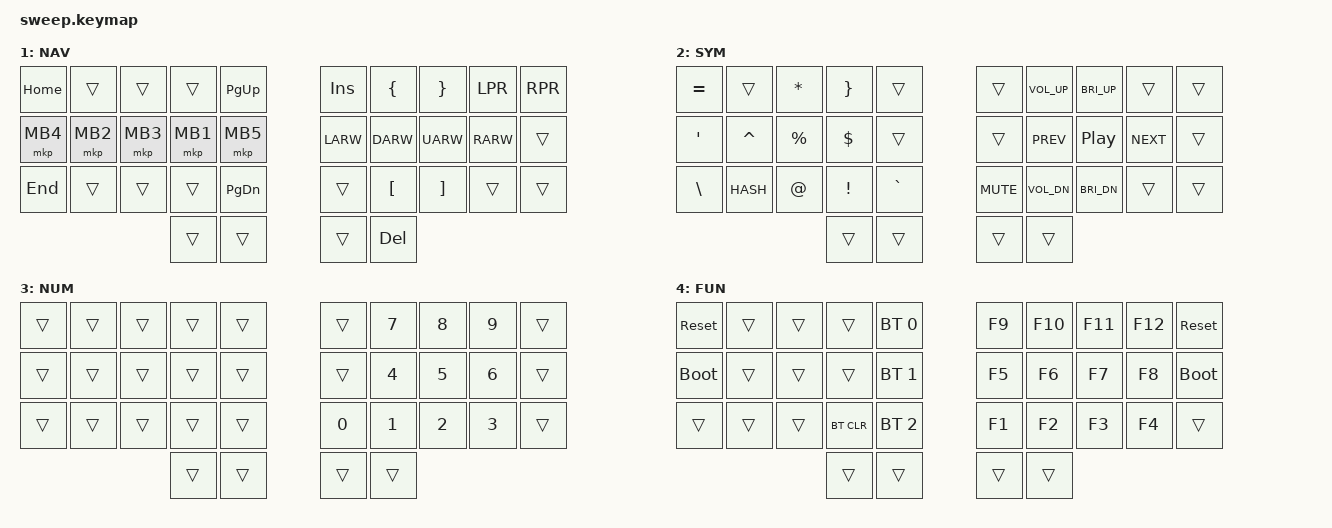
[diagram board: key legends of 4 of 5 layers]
// Copyright (c) 2022 The ZMK Contributors
// SPDX-License-Identifier: MIT

#include <behaviors.dtsi>
#include <dt-bindings/zmk/keys.h>
#include <dt-bindings/zmk/bt.h>

// Layers
#define DEFAULT 0
#define NAV 1
#define SYM 2
#define NUM 3
#define FUN 4

// Home row mods macro
#define HRML(k1,k2,k3,k4) &ht LSHFT k1  &ht LCTRL k2  &ht LALT k3  &ht LGUI k4
#define HRMR(k1,k2,k3,k4) &ht RGUI k1  &ht RALT k2  &ht RCTRL k3  &ht RSHFT k4

/ {
    behaviors {
        ht: hold_tap {
            compatible = "zmk,behavior-hold-tap";
            #binding-cells = <2>;
            flavor = "tap-preferred";
            tapping-term-ms = <220>;
            quick-tap-ms = <150>;
            require-prior-idle-ms = <100>;
            bindings = <&kp>, <&kp>;
        };
    };

    combos {
        compatible = "zmk,combos";
        combo_esc {
            timeout-ms = <50>;
            key-positions = <10 19>;
            bindings = <&kp ESC>;
        };
        combo_minus {
            timeout-ms = <50>;
            key-positions = <14 15>;
            bindings = <&kp MINUS>;
        };
        combo_underscore {
            timeout-ms = <50>;
            key-positions = <24 25>;
            bindings = <&kp UNDER>;
        };
        combo_capsword {
            timeout-ms = <50>;
            key-positions = <20 29>;
            bindings = <&caps_word>;
        };
    };

    keymap {
        compatible = "zmk,keymap";
        DEFAULT {
            bindings = <
        //╭──────────┬──────────┬──────────┬──────────┬──────────╮   ╭──────────┬──────────┬──────────┬──────────┬──────────╮
        //│  Q       │  W       │  F       │  P       │  B       │   │  J       │  L       │  U       │  Y       │  ; :     │
            &kp Q      &kp W      &kp F      &kp P      &kp B          &kp J      &kp L      &kp U      &kp Y      &kp SEMI
        //├──────────┼──────────┼──────────┼──────────┼──────────┤   ├──────────┼──────────┼──────────┼──────────┼──────────┤
        //│  A       │  R       │  S       │  T       │  G       │   │  M       │  N       │  E       │  I       │  O      │
            HRML(A,        R,         S,         T)     &kp G          &kp H      HRMR(N,        E,         I,        O)
        //├──────────┼──────────┼──────────┼──────────┼──────────┤   ├──────────┼──────────┼──────────┼──────────┼──────────┤
        //│  Z       │  X       │  C       │  D       │  V       │   │  K       │  H       │ , <      │ . >      │ / ?      │
            &kp Z      &kp X      &kp C      &kp D      &kp V          &kp N      &kp M      &kp COMMA  &kp DOT    &kp FSLH
        //╰──────────┴──────────┴──────────┼──────────┼──────────┤   ├──────────┼──────────┼──────────┴──────────┴──────────╯
                                        &lt NUM TAB   &lt NAV ENTER  &lt SYM SPACE  &lt FUN BSPC
        //                                 ╰──────────┴──────────╯   ╰──────────┴──────────╯
            >;
        };

        NAV {
            bindings = <
        // vim navigation and mouse actions
        //╭──────────┬──────────┬──────────┬──────────┬──────────╮   ╭──────────┬──────────┬──────────┬──────────┬──────────╮
        //│ Home     │          │          │          │ Page Up  │   │  Insert  │   {      │    }     │   (      │  )       │
            &kp HOME   &trans     &trans     &trans     &kp PG_UP       &kp INS   &kp LBRC   &kp RBRC   &kp LPR    &kp RPR
        //├──────────┼──────────┼──────────┼──────────┼──────────┤   ├──────────┼──────────┼──────────┼──────────┼──────────┤
        //│ MBCK     │  RCLK    │  MCLK    │  LCLK    │  MFWD    │   │ LEFT     │ DOWN     │ UP       │ RIGHT    │          │
            &mkp MB4   &mkp MB2   &mkp MB3   &mkp MB1   &mkp MB5       &kp LARW   &kp DARW   &kp UARW   &kp RARW   &trans
        //├──────────┼──────────┼──────────┼──────────┼──────────┤   ├──────────┼──────────┼──────────┼──────────┼──────────┤
        //│ End      │          |          │          │ Page Down│   │          │    [     │    ]     │          │          │
            &kp END     &trans     &trans     &trans    &kp PG_DN       &trans     &kp LBKT   &kp RBKT   &trans     &trans
        //╰──────────┴──────────┴──────────┼──────────┼──────────┤   ├──────────┼──────────┼──────────┴──────────┴──────────╯
                                             &trans     &trans         &trans     &kp DEL
        //                                 ╰──────────┴──────────╯   ╰──────────┴──────────╯
            >;
        };


        SYM {
            bindings = <
        // symbols and media controls
        //╭──────────┬──────────┬──────────┬──────────┬──────────╮   ╭──────────┬──────────┬──────────┬──────────┬──────────╮
        //│   = +    |          |    *     │    &     │          │   │          │  vol up  | brght up |          |          | 
            &kp EQUAL   &trans    &kp ASTRK   &kp RBRC   &trans        &trans   &kp C_VOL_UP &kp C_BRI_UP &trans     &trans
        //├──────────┼──────────┼──────────┼──────────┼──────────┤   ├──────────┼──────────┼──────────┼──────────┼──────────┤
        //│   ' "    │   ^      │    %     │    $     │          │   │          │    prev  │pause/play│   next   │          │
            &kp SQT   &kp CARET   &kp PRCNT   &kp DLLR   &trans        &trans    &kp C_PREV  &kp C_PP   &kp C_NEXT   &trans
        //├──────────┼──────────┼──────────┼──────────┼──────────┤   ├──────────┼──────────┼──────────┼──────────┼──────────┤
        //│   \ |    │    #     │    @     │    !     │    `     │   │  mute    │ vol down │ brght dwn│          │          │
            &kp BSLH     &HASH     &kp AT    &kp EXCL   &kp GRAVE    &kp C_MUTE &kp C_VOL_DN &kp C_BRI_DN  &trans   &trans
        //╰──────────┴──────────┴──────────┼──────────┼──────────┤   ├──────────┼──────────┼──────────┴──────────┴──────────╯
                                             &trans     &trans         &trans     &trans
        //                                 ╰──────────┴──────────╯   ╰──────────┴──────────╯
            >;
        };

        NUM {
            bindings = <
        //╭──────────┬──────────┬──────────┬──────────┬──────────╮   ╭──────────┬──────────┬──────────┬──────────┬──────────╮
        //│          │          │          │          │          │   │          │    7     │    8     │    9     │          │
            &trans     &trans     &trans     &trans     &trans         &trans     &kp N7    &kp N8     &kp N9      &trans
        //├──────────┼──────────┼──────────┼──────────┼──────────┤   ├──────────┼──────────┼──────────┼──────────┼──────────┤
        //│          │          │          │          │          │   │          │    4     │    5     │    6     │          │
            &trans     &trans     &trans     &trans     &trans         &trans     &kp N4     &kp N5     &kp N6     &trans
        //├──────────┼──────────┼──────────┼──────────┼──────────┤   ├──────────┼──────────┼──────────┼──────────┼──────────┤
        //│          │          │          │          │          │   │    0     │    1     │    2     │    3     │          │
            &trans     &trans     &trans     &trans     &trans         &kp N0     &kp N1     &kp N2     &kp N3     &trans
        //╰──────────┴──────────┴──────────┼──────────┼──────────┤   ├──────────┼──────────┼──────────┴──────────┴──────────╯
                                             &trans     &trans         &trans     &trans
        //                                 ╰──────────┴──────────╯   ╰──────────┴──────────╯
            >;
        };
        FUN {
            bindings = <
        //╭──────────┬──────────┬──────────┬──────────┬──────────╮   ╭──────────┬──────────┬──────────┬──────────┬──────────╮
        //│ RESET    │          │          │          │PROFILE 0 │   │    F9    │   F10    │   F11    │   F12    │   RESET  │
           &sys_reset  &trans     &trans     &trans    &bt BT_SEL 0    &kp F9     &kp F10    &kp F11    &kp F12   &sys_reset 
        //├──────────┼──────────┼──────────┼──────────┼──────────┤   ├──────────┼──────────┼──────────┼──────────┼──────────┤
        //│BOOTLOADER│          │          │          │PROFILE 1 │   │    F5    │   F6     │   F7     │   F8     │BOOTLOADER│          
          &bootloader  &trans     &trans     &trans    &bt BT_SEL 1    &kp F5     &kp F6     &kp F7     &kp F8    &bootloader
        //├──────────┼──────────┼──────────┼──────────┼──────────┤   ├──────────┼──────────┼──────────┼──────────┼──────────┤
        //│          │          │          │          │PROFILE 2 │   │    F1    │   F2     │   F3     │   F4     │          │
            &trans     &trans     &trans    &bt BT_CLR &bt BT_SEL 2    &kp F1     &kp F2     &kp F3     &kp F4     &trans
        //╰──────────┴──────────┴──────────┼──────────┼──────────┤   ├──────────┼──────────┼──────────┴──────────┴──────────╯
                                             &trans     &trans         &trans     &trans
        //                                 ╰──────────┴──────────╯   ╰──────────┴──────────╯
            >;
        };
    };
};
